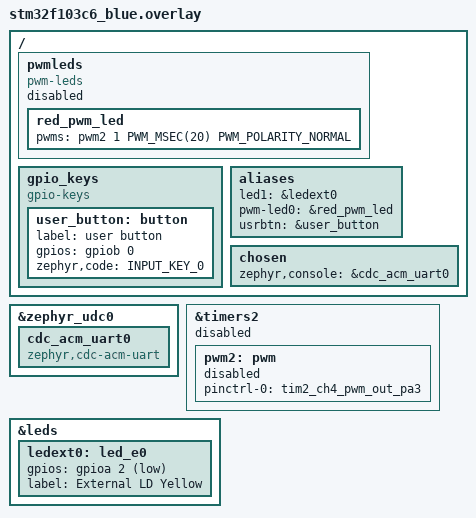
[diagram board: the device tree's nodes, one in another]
// SPDX-License-Identifier: Apache-2.0

#include <zephyr/dt-bindings/input/input-event-codes.h>

/ {
	pwmleds: pwmleds {
		compatible = "pwm-leds";
		status = "disabled";
		red_pwm_led: red_pwm_led {
			pwms = <&pwm2 1 PWM_MSEC(20) PWM_POLARITY_NORMAL>;
		};
	};
	gpio_keys {
		compatible = "gpio-keys";
		user_button: button {
			label = "user button";
			gpios = <&gpiob 0 GPIO_ACTIVE_HIGH>;
			status = "okay";
			zephyr,code = <INPUT_KEY_0>;
		};
	};
	aliases {
		led1 = &ledext0;
		pwm-led0 = &red_pwm_led;
		usrbtn = &user_button;
	};
	chosen {
		zephyr,console = &cdc_acm_uart0;
	};
};

&zephyr_udc0 {
	cdc_acm_uart0: cdc_acm_uart0 {
		compatible = "zephyr,cdc-acm-uart";
	};
};

&timers2 {
	status = "disabled";
	pwm2: pwm {
		status = "disabled";
		pinctrl-0 = <&tim2_ch4_pwm_out_pa3>;
		pinctrl-names = "default";
	};
};

&leds {
	ledext0: led_e0 {
		gpios = <&gpioa 2 GPIO_ACTIVE_LOW>;
		label = "External LD Yellow";
	};
};

